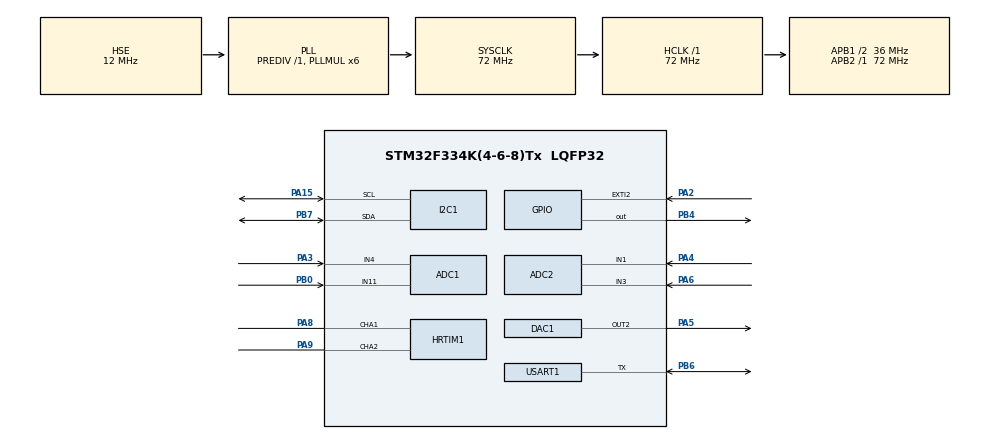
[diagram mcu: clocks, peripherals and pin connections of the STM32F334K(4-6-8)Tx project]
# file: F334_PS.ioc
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ADC1.Channel-3\#ChannelRegularConversion=ADC_CHANNEL_11
ADC1.Channel-4\#ChannelRegularConversion=ADC_CHANNEL_4
ADC1.ClockPrescaler=ADC_CLOCK_SYNC_PCLK_DIV4
ADC1.ContinuousConvMode=DISABLE
ADC1.DMAContinuousRequests=ENABLE
ADC1.EnableInjectedConversion=DISABLE
ADC1.EnableRegularConversion=ENABLE
ADC1.ExternalTrigConv=ADC_EXTERNALTRIGCONVHRTIM_TRG1
ADC1.NbrOfConversion=2
ADC1.NbrOfConversionFlag=1
ADC1.Offset-3\#ChannelRegularConversion=0
ADC1.Offset-4\#ChannelRegularConversion=0
ADC1.OffsetNumber-3\#ChannelRegularConversion=ADC_OFFSET_NONE
ADC1.OffsetNumber-4\#ChannelRegularConversion=ADC_OFFSET_NONE
ADC1.Rank-3\#ChannelRegularConversion=1
ADC1.Rank-4\#ChannelRegularConversion=2
ADC1.SamplingTime-3\#ChannelRegularConversion=ADC_SAMPLETIME_19CYCLES_5
ADC1.SamplingTime-4\#ChannelRegularConversion=ADC_SAMPLETIME_19CYCLES_5
ADC1.SubFamily=STM32F334x8
ADC1.master=1
ADC2.Channel-0\#ChannelRegularConversion=ADC_CHANNEL_3
ADC2.Channel-1\#ChannelRegularConversion=ADC_CHANNEL_1
ADC2.ClockPrescaler=ADC_CLOCK_SYNC_PCLK_DIV4
ADC2.ContinuousConvMode=DISABLE
ADC2.DMAContinuousRequests=ENABLE
ADC2.EnableInjectedConversion=DISABLE
ADC2.ExternalTrigConv=ADC_EXTERNALTRIGCONVHRTIM_TRG1
ADC2.NbrOfConversion=2
ADC2.NbrOfConversionFlag=1
ADC2.Offset-0\#ChannelRegularConversion=0
ADC2.Offset-1\#ChannelRegularConversion=0
ADC2.OffsetNumber-0\#ChannelRegularConversion=ADC_OFFSET_NONE
ADC2.OffsetNumber-1\#ChannelRegularConversion=ADC_OFFSET_NONE
ADC2.Rank-0\#ChannelRegularConversion=1
ADC2.Rank-1\#ChannelRegularConversion=2
ADC2.SamplingTime-0\#ChannelRegularConversion=ADC_SAMPLETIME_19CYCLES_5
ADC2.SamplingTime-1\#ChannelRegularConversion=ADC_SAMPLETIME_19CYCLES_5
ADC2.SubFamily=STM32F334x8
DAC1.DAC_Trigger2=DAC_TRIGGER_NONE
Dma.ADC1.0.Direction=DMA_PERIPH_TO_MEMORY
Dma.ADC1.0.Instance=DMA1_Channel1
Dma.ADC1.0.MemDataAlignment=DMA_MDATAALIGN_HALFWORD
Dma.ADC1.0.MemInc=DMA_MINC_ENABLE
Dma.ADC1.0.Mode=DMA_CIRCULAR
Dma.ADC1.0.PeriphDataAlignment=DMA_PDATAALIGN_HALFWORD
Dma.ADC1.0.PeriphInc=DMA_PINC_DISABLE
Dma.ADC1.0.Priority=DMA_PRIORITY_LOW
Dma.ADC2.1.Direction=DMA_PERIPH_TO_MEMORY
Dma.ADC2.1.Instance=DMA1_Channel2
Dma.ADC2.1.MemDataAlignment=DMA_MDATAALIGN_HALFWORD
Dma.ADC2.1.MemInc=DMA_MINC_ENABLE
Dma.ADC2.1.Mode=DMA_CIRCULAR
Dma.ADC2.1.PeriphDataAlignment=DMA_PDATAALIGN_HALFWORD
Dma.ADC2.1.PeriphInc=DMA_PINC_DISABLE
Dma.ADC2.1.Priority=DMA_PRIORITY_LOW
Dma.HRTIM1_A.2.Direction=DMA_MEMORY_TO_PERIPH
Dma.HRTIM1_A.2.Instance=DMA1_Channel3
Dma.HRTIM1_A.2.MemDataAlignment=DMA_MDATAALIGN_WORD
Dma.HRTIM1_A.2.MemInc=DMA_MINC_ENABLE
Dma.HRTIM1_A.2.Mode=DMA_CIRCULAR
Dma.HRTIM1_A.2.PeriphDataAlignment=DMA_PDATAALIGN_WORD
Dma.HRTIM1_A.2.PeriphInc=DMA_PINC_DISABLE
Dma.HRTIM1_A.2.Priority=DMA_PRIORITY_LOW
Dma.Request0=ADC1
Dma.Request1=ADC2
Dma.Request2=HRTIM1_A
HRTIM1.ADCTrigger1_Source1=HRTIM_ADCTRIGGEREVENT13_MASTER_PERIOD
HRTIM1.ADCTrigger_Id1=HRTIM_ADCTRIGGER_1
HRTIM1.ADCTrigger_Id2=__NULL
HRTIM1.CalibrationRate_nonIT=HRTIM_CALIBRATIONRATE_7300
HRTIM1.CompareUnit1-Output_TA1TA2=HRTIM_COMPAREUNIT_1
HRTIM1.CompareValue1-Output_TA1TA2=96
HRTIM1.DMADstAddress-Output_TA1TA2=0x0000
HRTIM1.DMARequests1-Output_TA1TA2=HRTIM_TIM_DMA_UPD
HRTIM1.DMASize-Output_TA1TA2=1
HRTIM1.DMASrcAddress-Output_TA1TA2=0x0000
HRTIM1.DeadTimeInsertion-Output_TA1TA2=HRTIM_TIMDEADTIMEINSERTION_ENABLED
HRTIM1.Deadtimeconfig-Output_TA1TA2=HRTIM_TIMERINDEX_TIMER_A
HRTIM1.Event_EEV1=__NULL
HRTIM1.FallingValue-Output_TA1TA2=75
HRTIM1.InterruptRequests1_Master=HRTIM_MASTER_IT_MREP
HRTIM1.NumberADCTriggerSource1=1
HRTIM1.NumberDMARequests_TA=1
HRTIM1.NumberInterruptRequests-Output_TA1TA2=0
HRTIM1.NumberInterruptRequests_Master-MasterTimer=1
HRTIM1.NumberResetSource1-Output_TA1TA2=1
HRTIM1.NumberSetSource1-Output_TA1TA2=1
HRTIM1.Periode_MASTER=46080
HRTIM1.Periode_TA=4608
HRTIM1.PreloadEnable-Output_TA1TA2=HRTIM_PRELOAD_ENABLED
HRTIM1.RepetitionUpdate-Output_TA1TA2=HRTIM_UPDATEONREPETITION_ENABLED
HRTIM1.ResetOutput1_Source1-Output_TA1TA2=HRTIM_OUTPUTRESET_TIMCMP1
HRTIM1.RisingValue-Output_TA1TA2=75
HRTIM1.SetOutput1_Source1-Output_TA1TA2=HRTIM_OUTPUTSET_TIMPER
Mcu.Family=STM32F3
Mcu.Name=STM32F334K(4-6-8)Tx
Mcu.Package=LQFP32
NVIC.DMA1_Channel1_IRQn=true\:2\:0\:true\:false\:true\:false\:true\:true
NVIC.DMA1_Channel2_IRQn=true\:2\:0\:true\:false\:true\:false\:true\:true
NVIC.DMA1_Channel3_IRQn=true\:0\:0\:false\:false\:true\:false\:true\:true
NVIC.HRTIM1_Master_IRQn=true\:0\:0\:false\:false\:true\:true\:true\:true
NVIC.PriorityGroup=NVIC_PRIORITYGROUP_4
PA13.Mode=Serial_Wire
PA13.Signal=SYS_JTMS-SWDIO
PA14.Mode=Serial_Wire
PA14.Signal=SYS_JTCK-SWCLK
PA15.GPIO_Pu=GPIO_PULLUP
PA15.Mode=I2C
PA15.Signal=I2C1_SCL
PA2.Signal=GPXTI2
PA3.Mode=IN4-Single-Ended
PA3.Signal=ADC1_IN4
PA4.Mode=IN1-Single-Ended
PA4.Signal=ADC2_IN1
PA5.Signal=COMP_DAC12_group
PA6.Mode=IN3-Single-Ended
PA6.Signal=ADC2_IN3
PA8.Mode=Output_TA1TA2
PA8.Signal=HRTIM1_CHA1
PA9.Mode=Output_TA1TA2
PA9.Signal=HRTIM1_CHA2
PB0.Mode=IN11-Single-Ended
PB0.Signal=ADC1_IN11
PB4.Signal=GPIO_Output
PB6.Mode=Half_duplex(single_wire_mode)
PB6.Signal=USART1_TX
PB7.GPIO_Pu=GPIO_PULLUP
PB7.Mode=I2C
PB7.Signal=I2C1_SDA
PF0\ /\ OSC_IN.Mode=HSE-External-Oscillator
PF0\ /\ OSC_IN.Signal=RCC_OSC_IN
PF1\ /\ OSC_OUT.Mode=HSE-External-Oscillator
PF1\ /\ OSC_OUT.Signal=RCC_OSC_OUT
ProjectManager.HeapSize=0x200
ProjectManager.StackSize=0x400
ProjectManager.TargetToolchain=Makefile
RCC.AHBFreq_Value=72000000
RCC.APB1CLKDivider=RCC_HCLK_DIV2
RCC.APB1Freq_Value=36000000
RCC.APB1TimFreq_Value=72000000
RCC.APB2Freq_Value=72000000
RCC.APB2TimFreq_Value=72000000
RCC.CortexFreq_Value=72000000
RCC.HCLKFreq_Value=72000000
RCC.HRTIMSelection=RCC_HRTIM1CLK_PLLCLK
RCC.HSE_VALUE=12000000
RCC.HSI_VALUE=8000000
RCC.PLLMUL=RCC_PLL_MUL6
RCC.PLLSourceVirtual=RCC_PLLSOURCE_HSE
RCC.SYSCLKFreq_VALUE=72000000
RCC.SYSCLKSourceVirtual=RCC_SYSCLKSOURCE_PLLCLK
SH.COMP_DAC12_group.0=DAC1_OUT2,DAC_OUT2
USART1.BaudRate=115200
USART1.VirtualMode-Half_duplex(single_wire_mode)=VM_ASYNC
VP_HRTIM1_VS_hrtimMasterTimerNoOutput.Mode=MasterTimer
board=custom

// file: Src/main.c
/* USER CODE BEGIN Header */
/**
 ******************************************************************************
 * @file           : main.c
 * @brief          : Main program body
 ******************************************************************************
 * @attention
 *
 * Copyright (c) 2022 STMicroelectronics.
 * All rights reserved.
 *
 * This software is licensed under terms that can be found in the LICENSE file
 * in the root directory of this software component.
 * If no LICENSE file comes with this software, it is provided AS-IS.
 *
 ******************************************************************************
 */
/* USER CODE END Header */
#include "main.h"
#include "adc.h"
#include "dac.h"
#include "dma.h"
#include "hrtim.h"
#include "i2c.h"
#include "usart.h"
#include "gpio.h"

/* USER CODE BEGIN Includes */
#include "main_cycle.hpp"
#include "utils.hpp"
#include "clock.hpp"
/* USER CODE END Includes */

void SystemClock_Config(void);

int main(void)
{

    /* MCU Configuration--------------------------------------------------------*/

    /* Reset of all peripherals, Initializes the Flash interface and the Systick. */
    HAL_Init();

    /* Configure the system clock */
    SystemClock_Config();

    /* USER CODE BEGIN SysInit */
    __HAL_RCC_DMA1_CLK_ENABLE();
    /* USER CODE END SysInit */

    /* Initialize all configured peripherals */
    MX_GPIO_Init();
    MX_DMA_Init();
    MX_USART1_UART_Init();
    MX_ADC1_Init();
    MX_ADC2_Init();
    MX_HRTIM1_Init();
    MX_DAC1_Init();
    MX_I2C1_Init();
    /* USER CODE BEGIN 2 */
    clock_init();
    init_common();
    /* USER CODE END 2 */

    /* Infinite loop */
    /* USER CODE BEGIN WHILE */
    while (1) {
        main_loop();
        /* USER CODE END WHILE */

    }
}

void SystemClock_Config(void)
{
    RCC_OscInitTypeDef RCC_OscInitStruct = {0};
    RCC_ClkInitTypeDef RCC_ClkInitStruct = {0};
    RCC_PeriphCLKInitTypeDef PeriphClkInit = {0};

    /** Initializes the RCC Oscillators according to the specified parameters
     * in the RCC_OscInitTypeDef structure.
     */
    RCC_OscInitStruct.OscillatorType = RCC_OSCILLATORTYPE_HSI | RCC_OSCILLATORTYPE_HSE;
    RCC_OscInitStruct.HSEState = RCC_HSE_ON;
    RCC_OscInitStruct.HSEPredivValue = RCC_HSE_PREDIV_DIV1;
    RCC_OscInitStruct.HSIState = RCC_HSI_ON;
    RCC_OscInitStruct.HSICalibrationValue = RCC_HSICALIBRATION_DEFAULT;
    RCC_OscInitStruct.PLL.PLLState = RCC_PLL_ON;
    RCC_OscInitStruct.PLL.PLLSource = RCC_PLLSOURCE_HSE;
    RCC_OscInitStruct.PLL.PLLMUL = RCC_PLL_MUL6;
    if (HAL_RCC_OscConfig(&RCC_OscInitStruct) != HAL_OK) {
        Error_Handler();
    }

    /** Initializes the CPU, AHB and APB buses clocks
     */
    RCC_ClkInitStruct.ClockType = RCC_CLOCKTYPE_HCLK | RCC_CLOCKTYPE_SYSCLK
                                  | RCC_CLOCKTYPE_PCLK1 | RCC_CLOCKTYPE_PCLK2;
    RCC_ClkInitStruct.SYSCLKSource = RCC_SYSCLKSOURCE_PLLCLK;
    RCC_ClkInitStruct.AHBCLKDivider = RCC_SYSCLK_DIV1;
    RCC_ClkInitStruct.APB1CLKDivider = RCC_HCLK_DIV2;
    RCC_ClkInitStruct.APB2CLKDivider = RCC_HCLK_DIV1;

    if (HAL_RCC_ClockConfig(&RCC_ClkInitStruct, FLASH_LATENCY_2) != HAL_OK) {
        Error_Handler();
    }
    PeriphClkInit.PeriphClockSelection = RCC_PERIPHCLK_HRTIM1 | RCC_PERIPHCLK_USART1
                                         | RCC_PERIPHCLK_I2C1;
    PeriphClkInit.Usart1ClockSelection = RCC_USART1CLKSOURCE_PCLK1;
    PeriphClkInit.I2c1ClockSelection = RCC_I2C1CLKSOURCE_HSI;
    PeriphClkInit.Hrtim1ClockSelection = RCC_HRTIM1CLK_PLLCLK;
    if (HAL_RCCEx_PeriphCLKConfig(&PeriphClkInit) != HAL_OK) {
        Error_Handler();
    }
}

void Error_Handler(void)
{
    __disable_irq();
    while (1) {
    }
}
